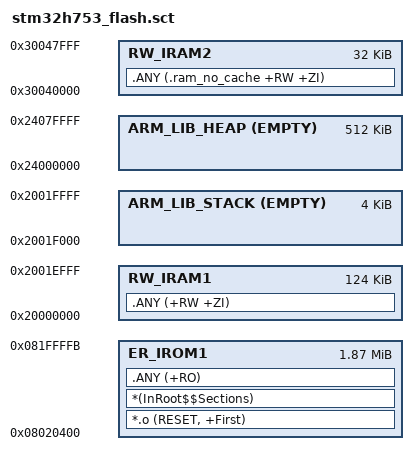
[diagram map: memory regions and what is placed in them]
;********************************************************************
;* STM32H753 linker scatter file (running code from internal FLASH) *
;********************************************************************

LR_IROM1 0x08020400 0x1DFBFC
{
   ER_IROM1 0x08020400 0x1DFBFC
   {
      *.o (RESET, +First)
      *(InRoot$$Sections)
      .ANY (+RO)
   }
   
   RW_IRAM1 0x20000000 0x1F000
   { 
      .ANY (+RW +ZI)
   }
   
   ARM_LIB_STACK 0x20020000 EMPTY -0x1000
   {
   }
   
   RW_IRAM2 0x30040000 0x8000
   {
      .ANY (.ram_no_cache +RW +ZI)
   }
   
   ARM_LIB_HEAP 0x24000000 EMPTY 0x80000
   {
   }
}
